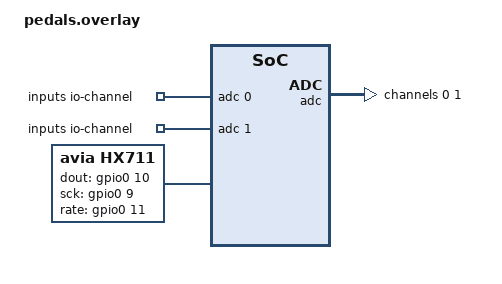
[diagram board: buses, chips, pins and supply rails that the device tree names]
#include "common.overlay"

/ {
	inputs: zephyr,user {
		io-channels = <&adc 0>, <&adc 1>;
	};

	hx711: hx711 {
		compatible = "avia,hx711";
		status = "okay";
		gain = <128>;
		rate-hz = <80>;
		dout-gpios = <&gpio0 10 (GPIO_ACTIVE_HIGH | GPIO_PULL_UP)>;
		sck-gpios = <&gpio0 9 (GPIO_ACTIVE_HIGH | GPIO_PULL_UP)>;
		rate-gpios = <&gpio0 11 (GPIO_ACTIVE_HIGH)>;
	};
};

&uart0_default {
	group1 {
		psels = <NRF_PSEL(UART_TX, 1, 13)>,
				<NRF_PSEL(UART_RX, 1, 15)>;
	};
};

&uart0_sleep {
	group1 {
		psels = <NRF_PSEL(UART_TX, 1, 13)>,
		        <NRF_PSEL(UART_RX, 1, 15)>;
		low-power-enable;
	};
};

&uart0 {
	status = "disabled";
};

&adc {
	#address-cells = <1>;
	#size-cells = <0>;
	status = "okay";

	channel@0 {
		reg = <0>;
		zephyr,gain = "ADC_GAIN_1_6";
		zephyr,reference = "ADC_REF_INTERNAL";
		zephyr,acquisition-time = <ADC_ACQ_TIME_DEFAULT>;
		zephyr,input-positive = <NRF_SAADC_AIN7>;  // 0_31
		zephyr,resolution = <12>;
	};

	channel@1 {
		reg = <1>;
		zephyr,gain = "ADC_GAIN_1_6";
		zephyr,reference = "ADC_REF_INTERNAL";
		zephyr,acquisition-time = <ADC_ACQ_TIME_DEFAULT>;
		zephyr,input-positive = <NRF_SAADC_AIN5>;  // 0_29
		zephyr,resolution = <12>;
	};
};
